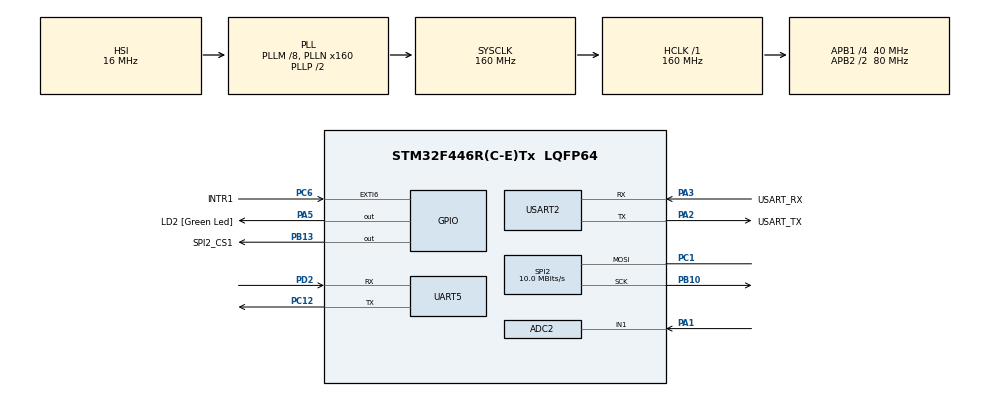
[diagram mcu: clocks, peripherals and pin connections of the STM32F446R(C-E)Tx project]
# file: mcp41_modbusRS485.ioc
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ADC2.Channel-0\#ChannelRegularConversion=ADC_CHANNEL_1
ADC2.ContinuousConvMode=ENABLE
ADC2.DMAContinuousRequests=ENABLE
ADC2.NbrOfConversionFlag=1
ADC2.Rank-0\#ChannelRegularConversion=1
ADC2.SamplingTime-0\#ChannelRegularConversion=ADC_SAMPLETIME_144CYCLES
Dma.ADC2.0.Direction=DMA_PERIPH_TO_MEMORY
Dma.ADC2.0.FIFOMode=DMA_FIFOMODE_DISABLE
Dma.ADC2.0.Instance=DMA2_Stream2
Dma.ADC2.0.MemDataAlignment=DMA_MDATAALIGN_WORD
Dma.ADC2.0.MemInc=DMA_MINC_ENABLE
Dma.ADC2.0.Mode=DMA_CIRCULAR
Dma.ADC2.0.PeriphDataAlignment=DMA_PDATAALIGN_WORD
Dma.ADC2.0.PeriphInc=DMA_PINC_DISABLE
Dma.ADC2.0.Priority=DMA_PRIORITY_LOW
Dma.Request0=ADC2
FREERTOS.Tasks01=defaultTask,24,128,StartDefaultTask,Default,NULL,Dynamic,NULL,NULL
Mcu.Family=STM32F4
Mcu.Name=STM32F446R(C-E)Tx
Mcu.Package=LQFP64
NVIC.DMA2_Stream2_IRQn=true\:5\:0\:false\:false\:true\:true\:false\:true
NVIC.PriorityGroup=NVIC_PRIORITYGROUP_4
NVIC.TIM6_DAC_IRQn=true\:5\:0\:false\:false\:true\:true\:true\:true
NVIC.TIM7_IRQn=true\:5\:0\:false\:false\:true\:true\:true\:true
NVIC.TIM8_UP_TIM13_IRQn=true\:0\:0\:false\:false\:true\:false\:false\:true
NVIC.TimeBase=TIM8_UP_TIM13_IRQn
NVIC.TimeBaseIP=TIM13
NVIC.UART5_IRQn=true\:5\:0\:false\:false\:true\:true\:true\:true
PA1.Signal=ADCx_IN1
PA13.GPIO_Label=TMS
PA13.Mode=Serial_Wire
PA13.Signal=SYS_JTMS-SWDIO
PA14.GPIO_Label=TCK
PA14.Mode=Serial_Wire
PA14.Signal=SYS_JTCK-SWCLK
PA2.GPIO_Label=USART_TX
PA2.Mode=Asynchronous
PA2.Signal=USART2_TX
PA3.GPIO_Label=USART_RX
PA3.Mode=Asynchronous
PA3.Signal=USART2_RX
PA5.GPIO_Label=LD2 [Green Led]
PA5.Signal=GPIO_Output
PB10.Mode=Simplex_Bidirectional_Master
PB10.Signal=SPI2_SCK
PB13.GPIO_Label=SPI2_CS1
PB13.Signal=GPIO_Output
PB3.GPIO_Label=SWO
PB3.Signal=SYS_JTDO-SWO
PC1.Mode=Simplex_Bidirectional_Master
PC1.Signal=SPI2_MOSI
PC12.Mode=Asynchronous
PC12.Signal=UART5_TX
PC14-OSC32_IN.Mode=LSE-External-Oscillator
PC14-OSC32_IN.Signal=RCC_OSC32_IN
PC15-OSC32_OUT.Mode=LSE-External-Oscillator
PC15-OSC32_OUT.Signal=RCC_OSC32_OUT
PC6.GPIO_Label=INTR1
PC6.Signal=GPXTI6
PD2.Mode=Asynchronous
PD2.Signal=UART5_RX
PH0-OSC_IN.Mode=HSE-External-Oscillator
PH0-OSC_IN.Signal=RCC_OSC_IN
PH1-OSC_OUT.Mode=HSE-External-Oscillator
PH1-OSC_OUT.Signal=RCC_OSC_OUT
ProjectManager.HeapSize=0x200
ProjectManager.StackSize=0x400
ProjectManager.TargetToolchain=STM32CubeIDE
RCC.48MHZClocksFreq_Value=84000000
RCC.AHBFreq_Value=160000000
RCC.APB1CLKDivider=RCC_HCLK_DIV4
RCC.APB1Freq_Value=40000000
RCC.APB1TimFreq_Value=80000000
RCC.APB2CLKDivider=RCC_HCLK_DIV2
RCC.APB2Freq_Value=80000000
RCC.APB2TimFreq_Value=160000000
RCC.CortexFreq_Value=160000000
RCC.FLatency-AdvancedSettings=FLASH_LATENCY_5
RCC.HCLKFreq_Value=160000000
RCC.HSE_VALUE=8000000
RCC.HSI_VALUE=16000000
RCC.PLLM=8
RCC.PLLN=160
RCC.SYSCLKFreq_VALUE=160000000
RCC.SYSCLKSource=RCC_SYSCLKSOURCE_PLLCLK
RCC.USBFreq_Value=160000000
RCC.VCOOutputFreq_Value=320000000
SH.ADCx_IN1.0=ADC2_IN1,IN1
SPI2.BaudRatePrescaler=SPI_BAUDRATEPRESCALER_4
SPI2.CalculateBaudRate=10.0 MBits/s
SPI2.DataSize=SPI_DATASIZE_16BIT
SPI2.Direction=SPI_DIRECTION_1LINE
SPI2.Mode=SPI_MODE_MASTER
SPI2.VirtualType=VM_MASTER
TIM6.AutoReloadPreload=TIM_AUTORELOAD_PRELOAD_ENABLE
TIM6.Period=1
TIM6.Prescaler=39999
TIM6.TIM_MasterOutputTrigger=TIM_TRGO_UPDATE
UART5.VirtualMode=Asynchronous
USART2.VirtualMode=VM_ASYNC
VP_FREERTOS_VS_CMSIS_V2.Mode=CMSIS_V2
VP_SYS_VS_tim13.Mode=TIM13
VP_TIM6_VS_ClockSourceINT.Mode=Enable_Timer
VP_TIM7_VS_ClockSourceINT.Mode=Enable_Timer
board=NUCLEO-F446RE

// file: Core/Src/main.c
/* USER CODE BEGIN Header */
/**
  ******************************************************************************
  * @file           : main.c
  * @brief          : Main program body
  ******************************************************************************
  * @attention
  *
  * <h2><center>&copy; Copyright (c) 2021 STMicroelectronics.
  * All rights reserved.</center></h2>
  *
  * This software component is licensed by ST under BSD 3-Clause license,
  * the "License"; You may not use this file except in compliance with the
  * License. You may obtain a copy of the License at:
  *                        opensource.org/licenses/BSD-3-Clause
  *
  ******************************************************************************
  */
/* USER CODE END Header */
#include "main.h"
#include "cmsis_os.h"

/* USER CODE BEGIN Includes */
#include "project_task.h"
/* USER CODE END Includes */

ADC_HandleTypeDef hadc2;
DMA_HandleTypeDef hdma_adc2;

SPI_HandleTypeDef hspi2;

TIM_HandleTypeDef htim6;
TIM_HandleTypeDef htim7;

UART_HandleTypeDef huart5;
UART_HandleTypeDef huart2;

/* Definitions for defaultTask */
osThreadId_t defaultTaskHandle;
const osThreadAttr_t defaultTask_attributes = {
  .name = "defaultTask",
  .stack_size = 128 * 4,
  .priority = (osPriority_t) osPriorityNormal,
};

void SystemClock_Config(void);
static void MX_GPIO_Init(void);
static void MX_DMA_Init(void);
static void MX_USART2_UART_Init(void);
static void MX_ADC2_Init(void);
static void MX_SPI2_Init(void);
static void MX_TIM6_Init(void);
static void MX_TIM7_Init(void);
static void MX_UART5_Init(void);
void StartDefaultTask(void *argument);

int main(void)
{

  /* MCU Configuration--------------------------------------------------------*/

  /* Reset of all peripherals, Initializes the Flash interface and the Systick. */
  HAL_Init();

  /* Configure the system clock */
  SystemClock_Config();

  /* Initialize all configured peripherals */
  MX_GPIO_Init();
  MX_DMA_Init();
  MX_USART2_UART_Init();
  MX_ADC2_Init();
  MX_SPI2_Init();
  MX_TIM6_Init();
  MX_TIM7_Init();
  MX_UART5_Init();

  /* Init scheduler */
  osKernelInitialize();

  /* Create the thread(s) */
  /* creation of defaultTask */
  defaultTaskHandle = osThreadNew(StartDefaultTask, NULL, &defaultTask_attributes);

  /* Start scheduler */
  osKernelStart();

  /* We should never get here as control is now taken by the scheduler */
  /* Infinite loop */
  while (1)
  {

  }
}

void SystemClock_Config(void)
{
  RCC_OscInitTypeDef RCC_OscInitStruct = {0};
  RCC_ClkInitTypeDef RCC_ClkInitStruct = {0};

  /** Configure the main internal regulator output voltage
  */
  __HAL_RCC_PWR_CLK_ENABLE();
  __HAL_PWR_VOLTAGESCALING_CONFIG(PWR_REGULATOR_VOLTAGE_SCALE1);
  /** Initializes the RCC Oscillators according to the specified parameters
  * in the RCC_OscInitTypeDef structure.
  */
  RCC_OscInitStruct.OscillatorType = RCC_OSCILLATORTYPE_HSI;
  RCC_OscInitStruct.HSIState = RCC_HSI_ON;
  RCC_OscInitStruct.HSICalibrationValue = RCC_HSICALIBRATION_DEFAULT;
  RCC_OscInitStruct.PLL.PLLState = RCC_PLL_ON;
  RCC_OscInitStruct.PLL.PLLSource = RCC_PLLSOURCE_HSI;
  RCC_OscInitStruct.PLL.PLLM = 8;
  RCC_OscInitStruct.PLL.PLLN = 160;
  RCC_OscInitStruct.PLL.PLLP = RCC_PLLP_DIV2;
  RCC_OscInitStruct.PLL.PLLQ = 2;
  RCC_OscInitStruct.PLL.PLLR = 2;
  if (HAL_RCC_OscConfig(&RCC_OscInitStruct) != HAL_OK)
  {
    Error_Handler();
  }
  /** Initializes the CPU, AHB and APB buses clocks
  */
  RCC_ClkInitStruct.ClockType = RCC_CLOCKTYPE_HCLK|RCC_CLOCKTYPE_SYSCLK
                              |RCC_CLOCKTYPE_PCLK1|RCC_CLOCKTYPE_PCLK2;
  RCC_ClkInitStruct.SYSCLKSource = RCC_SYSCLKSOURCE_PLLCLK;
  RCC_ClkInitStruct.AHBCLKDivider = RCC_SYSCLK_DIV1;
  RCC_ClkInitStruct.APB1CLKDivider = RCC_HCLK_DIV4;
  RCC_ClkInitStruct.APB2CLKDivider = RCC_HCLK_DIV2;

  if (HAL_RCC_ClockConfig(&RCC_ClkInitStruct, FLASH_LATENCY_5) != HAL_OK)
  {
    Error_Handler();
  }
}

static void MX_ADC2_Init(void)
{

  ADC_ChannelConfTypeDef sConfig = {0};

  /** Configure the global features of the ADC (Clock, Resolution, Data Alignment and number of conversion)
  */
  hadc2.Instance = ADC2;
  hadc2.Init.ClockPrescaler = ADC_CLOCK_SYNC_PCLK_DIV4;
  hadc2.Init.Resolution = ADC_RESOLUTION_12B;
  hadc2.Init.ScanConvMode = DISABLE;
  hadc2.Init.ContinuousConvMode = ENABLE;
  hadc2.Init.DiscontinuousConvMode = DISABLE;
  hadc2.Init.ExternalTrigConvEdge = ADC_EXTERNALTRIGCONVEDGE_NONE;
  hadc2.Init.ExternalTrigConv = ADC_SOFTWARE_START;
  hadc2.Init.DataAlign = ADC_DATAALIGN_RIGHT;
  hadc2.Init.NbrOfConversion = 1;
  hadc2.Init.DMAContinuousRequests = ENABLE;
  hadc2.Init.EOCSelection = ADC_EOC_SINGLE_CONV;
  if (HAL_ADC_Init(&hadc2) != HAL_OK)
  {
    Error_Handler();
  }
  /** Configure for the selected ADC regular channel its corresponding rank in the sequencer and its sample time.
  */
  sConfig.Channel = ADC_CHANNEL_1;
  sConfig.Rank = 1;
  sConfig.SamplingTime = ADC_SAMPLETIME_144CYCLES;
  if (HAL_ADC_ConfigChannel(&hadc2, &sConfig) != HAL_OK)
  {
    Error_Handler();
  }

}

static void MX_SPI2_Init(void)
{

  /* SPI2 parameter configuration*/
  hspi2.Instance = SPI2;
  hspi2.Init.Mode = SPI_MODE_MASTER;
  hspi2.Init.Direction = SPI_DIRECTION_1LINE;
  hspi2.Init.DataSize = SPI_DATASIZE_16BIT;
  hspi2.Init.CLKPolarity = SPI_POLARITY_LOW;
  hspi2.Init.CLKPhase = SPI_PHASE_1EDGE;
  hspi2.Init.NSS = SPI_NSS_SOFT;
  hspi2.Init.BaudRatePrescaler = SPI_BAUDRATEPRESCALER_4;
  hspi2.Init.FirstBit = SPI_FIRSTBIT_MSB;
  hspi2.Init.TIMode = SPI_TIMODE_DISABLE;
  hspi2.Init.CRCCalculation = SPI_CRCCALCULATION_DISABLE;
  hspi2.Init.CRCPolynomial = 10;
  if (HAL_SPI_Init(&hspi2) != HAL_OK)
  {
    Error_Handler();
  }

}

static void MX_TIM6_Init(void)
{

  TIM_MasterConfigTypeDef sMasterConfig = {0};

  htim6.Instance = TIM6;
  htim6.Init.Prescaler = 39999;
  htim6.Init.CounterMode = TIM_COUNTERMODE_UP;
  htim6.Init.Period = 1;
  htim6.Init.AutoReloadPreload = TIM_AUTORELOAD_PRELOAD_ENABLE;
  if (HAL_TIM_Base_Init(&htim6) != HAL_OK)
  {
    Error_Handler();
  }
  sMasterConfig.MasterOutputTrigger = TIM_TRGO_UPDATE;
  sMasterConfig.MasterSlaveMode = TIM_MASTERSLAVEMODE_DISABLE;
  if (HAL_TIMEx_MasterConfigSynchronization(&htim6, &sMasterConfig) != HAL_OK)
  {
    Error_Handler();
  }

}

static void MX_TIM7_Init(void)
{

  TIM_MasterConfigTypeDef sMasterConfig = {0};

  htim7.Instance = TIM7;
  htim7.Init.Prescaler = 0;
  htim7.Init.CounterMode = TIM_COUNTERMODE_UP;
  htim7.Init.Period = 65535;
  htim7.Init.AutoReloadPreload = TIM_AUTORELOAD_PRELOAD_DISABLE;
  if (HAL_TIM_Base_Init(&htim7) != HAL_OK)
  {
    Error_Handler();
  }
  sMasterConfig.MasterOutputTrigger = TIM_TRGO_RESET;
  sMasterConfig.MasterSlaveMode = TIM_MASTERSLAVEMODE_DISABLE;
  if (HAL_TIMEx_MasterConfigSynchronization(&htim7, &sMasterConfig) != HAL_OK)
  {
    Error_Handler();
  }

}

static void MX_UART5_Init(void)
{

  huart5.Instance = UART5;
  huart5.Init.BaudRate = 115200;
  huart5.Init.WordLength = UART_WORDLENGTH_8B;
  huart5.Init.StopBits = UART_STOPBITS_1;
  huart5.Init.Parity = UART_PARITY_NONE;
  huart5.Init.Mode = UART_MODE_TX_RX;
  huart5.Init.HwFlowCtl = UART_HWCONTROL_NONE;
  huart5.Init.OverSampling = UART_OVERSAMPLING_16;
  if (HAL_UART_Init(&huart5) != HAL_OK)
  {
    Error_Handler();
  }

}

static void MX_USART2_UART_Init(void)
{

  huart2.Instance = USART2;
  huart2.Init.BaudRate = 115200;
  huart2.Init.WordLength = UART_WORDLENGTH_8B;
  huart2.Init.StopBits = UART_STOPBITS_1;
  huart2.Init.Parity = UART_PARITY_NONE;
  huart2.Init.Mode = UART_MODE_TX_RX;
  huart2.Init.HwFlowCtl = UART_HWCONTROL_NONE;
  huart2.Init.OverSampling = UART_OVERSAMPLING_16;
  if (HAL_UART_Init(&huart2) != HAL_OK)
  {
    Error_Handler();
  }

}

static void MX_DMA_Init(void)
{

  /* DMA controller clock enable */
  __HAL_RCC_DMA2_CLK_ENABLE();

  /* DMA interrupt init */
  /* DMA2_Stream2_IRQn interrupt configuration */
  HAL_NVIC_SetPriority(DMA2_Stream2_IRQn, 5, 0);
  HAL_NVIC_EnableIRQ(DMA2_Stream2_IRQn);

}

static void MX_GPIO_Init(void)
{
  GPIO_InitTypeDef GPIO_InitStruct = {0};

  /* GPIO Ports Clock Enable */
  __HAL_RCC_GPIOC_CLK_ENABLE();
  __HAL_RCC_GPIOH_CLK_ENABLE();
  __HAL_RCC_GPIOA_CLK_ENABLE();
  __HAL_RCC_GPIOB_CLK_ENABLE();
  __HAL_RCC_GPIOD_CLK_ENABLE();

  /*Configure GPIO pin Output Level */
  HAL_GPIO_WritePin(LD2_GPIO_Port, LD2_Pin|LD3_Pin, GPIO_PIN_RESET);

  /*Configure GPIO pin Output Level */
  HAL_GPIO_WritePin(SPI2_CS1_GPIO_Port, SPI2_CS1_Pin, GPIO_PIN_RESET);

  /*Configure GPIO pin : LD2_Pin */
  GPIO_InitStruct.Pin = LD2_Pin|LD3_Pin;
  GPIO_InitStruct.Mode = GPIO_MODE_OUTPUT_PP;
  GPIO_InitStruct.Pull = GPIO_NOPULL;
  GPIO_InitStruct.Speed = GPIO_SPEED_FREQ_LOW;
  HAL_GPIO_Init(LD2_GPIO_Port, &GPIO_InitStruct);

  /*Configure GPIO pin : SPI2_CS1_Pin */
  GPIO_InitStruct.Pin = SPI2_CS1_Pin;
  GPIO_InitStruct.Mode = GPIO_MODE_OUTPUT_PP;
  GPIO_InitStruct.Pull = GPIO_NOPULL;
  GPIO_InitStruct.Speed = GPIO_SPEED_FREQ_LOW;
  HAL_GPIO_Init(SPI2_CS1_GPIO_Port, &GPIO_InitStruct);

  /*Configure GPIO pin : INTR1_Pin */
  GPIO_InitStruct.Pin = INTR1_Pin;
  GPIO_InitStruct.Mode = GPIO_MODE_IT_RISING;
  GPIO_InitStruct.Pull = GPIO_NOPULL;
  HAL_GPIO_Init(INTR1_GPIO_Port, &GPIO_InitStruct);

}

void StartDefaultTask(void *argument)
{
  /* USER CODE BEGIN 5 */
	vTaskInitAll();
  /* Infinite loop */
  for(;;)
  {
    HAL_GPIO_WritePin(LD3_GPIO_Port, LD3_Pin, GPIO_PIN_SET);
    osThreadExit();
  }
  /* USER CODE END 5 */
}

 /**
  * @brief  Period elapsed callback in non blocking mode
  * @note   This function is called  when TIM13 interrupt took place, inside
  * HAL_TIM_IRQHandler(). It makes a direct call to HAL_IncTick() to increment
  * a global variable "uwTick" used as application time base.
  * @param  htim : TIM handle
  * @retval None
  */

void Error_Handler(void)
{
  __disable_irq();
  while (1)
  {
  }
}

/************************ (C) COPYRIGHT STMicroelectronics *****END OF FILE****/
